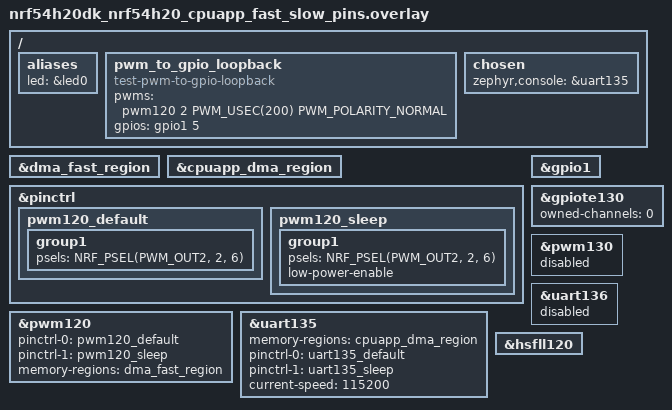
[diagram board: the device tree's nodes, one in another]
/*
 * Copyright (c) 2024 Nordic Semiconductor ASA
 *
 * SPDX-License-Identifier: LicenseRef-Nordic-5-Clause
 */

#include <zephyr/dt-bindings/pwm/pwm.h>
#include <zephyr/dt-bindings/gpio/nordic-nrf-gpio.h>

/* Test requires wire connection between:
 *  - PWM120 OUT[2] at P2.06
 *  - GPIO input at P1.05
 */

/ {
	aliases {
		led = &led0;
		/delete-property/ led1;
	};

	pwm_to_gpio_loopback: pwm_to_gpio_loopback {
		compatible = "test-pwm-to-gpio-loopback";
		pwms = <&pwm120 2 PWM_USEC(200) PWM_POLARITY_NORMAL>;
		gpios = <&gpio1 5 GPIO_ACTIVE_HIGH>;
	};

	chosen {
		zephyr,console = &uart135;
	};
};

/delete-node/ &led1;

&dma_fast_region {
	status = "okay";
};

&cpuapp_dma_region {
	status = "okay";
};

&pinctrl {
	/omit-if-no-ref/ pwm120_default: pwm120_default {
		group1 {
			psels = <NRF_PSEL(PWM_OUT2, 2, 6)>;
		};
	};
	/omit-if-no-ref/ pwm120_sleep: pwm120_sleep {
		group1 {
			psels = <NRF_PSEL(PWM_OUT2, 2, 6)>;
			low-power-enable;
		};
	};
};

&gpio1 {
	status = "okay";
};

&gpiote130 {
	status = "okay";
	owned-channels = <0>;
};

&pwm120 {
	status = "okay";
	pinctrl-0 = <&pwm120_default>;
	pinctrl-1 = <&pwm120_sleep>;
	pinctrl-names = "default", "sleep";
	memory-regions = <&dma_fast_region>;
};

&pwm130 {
	status = "disabled";
};

&uart136 {
	status = "disabled";
	/delete-property/ memory-regions;
	/delete-property/ hw-flow-control;
};

&uart135 {
	status = "okay";
	memory-regions = <&cpuapp_dma_region>;
	pinctrl-0 = <&uart135_default>;
	pinctrl-1 = <&uart135_sleep>;
	pinctrl-names = "default", "sleep";
	current-speed = <115200>;
	/delete-property/ hw-flow-control;
};

&hsfll120 {
	status = "okay";
};
